# MSPM0G350X register map
Vendor: Texas Instruments; File version: This preliminary header file does not have a version number - build date: 2023-02-21 16:25:48
CPU: CM0 r0p1, little endian, MPU, no FPU, 3 interrupt priority bits
Registers are 32-bit, read-write, reset 0x0 unless marked. A register's access mark holds for its fields unless they carry their own. Offsets are from the block's base; [hi:lo] are bit positions; {n}, {i} and the like mark numbered series.

## AES — PERIPHERALREGION
Base 0x40442000
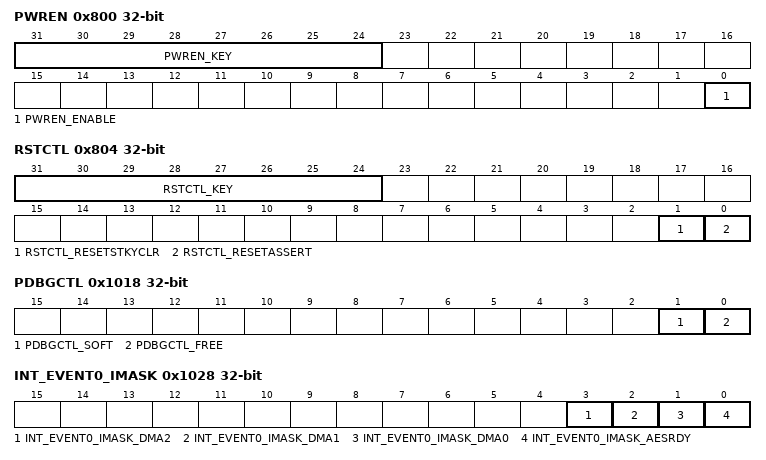
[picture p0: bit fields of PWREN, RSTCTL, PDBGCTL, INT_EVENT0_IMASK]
0x800 PWREN — Power enable
  [31:24] PWREN_KEY wo — KEY to allow Power State Change
    38=PWREN_KEY_UNLOCK_W (_TO_UNLOCK_W_)
  [0] PWREN_ENABLE — Enable the power
    0=PWREN_ENABLE_DISABLE (DISABLE); 1=PWREN_ENABLE_ENABLE (ENABLE)
0x804 RSTCTL wo — Reset Control
  [31:24] RSTCTL_KEY — Unlock key
    177=RSTCTL_KEY_UNLOCK_W (_TO_UNLOCK_W_)
  [1] RSTCTL_RESETSTKYCLR — Clear the RESETSTKY bit in the STAT register
    0=RSTCTL_RESETSTKYCLR_NOP (NOP); 1=RSTCTL_RESETSTKYCLR_CLR (CLR)
  [0] RSTCTL_RESETASSERT — Assert reset to the peripheral
    0=RSTCTL_RESETASSERT_NOP (NOP); 1=RSTCTL_RESETASSERT_ASSERT (ASSERT)
0x814 STAT ro — Status Register
  [16] STAT_RESETSTKY — This bit indicates, if the peripheral was reset, since this bit was cleared by RESETSTKYCLR in the RSTCTL register
    0=STAT_RESETSTKY_NORES (NORES); 1=STAT_RESETSTKY_RESET (RESET)
0x1018 PDBGCTL — Peripheral Debug Control
  [1] PDBGCTL_SOFT — Soft halt boundary control. This function is only available, if [FREE] is set to 'STOP'
    0=PDBGCTL_SOFT_IMMEDIATE (IMMEDIATE); 1=PDBGCTL_SOFT_DELAYED (DELAYED)
  [0] PDBGCTL_FREE — Free run control
    0=PDBGCTL_FREE_STOP (STOP); 1=PDBGCTL_FREE_RUN (RUN)
0x1020 INT_EVENT0_IIDX ro — Interrupt Index Register
  [7:0] INT_EVENT0_IIDX_STAT — Interrupt index status
    0=INT_EVENT0_IIDX_STAT_NO_INTR (NO_INTR); 1=INT_EVENT0_IIDX_STAT_AESRDY (AESRDY); 2=INT_EVENT0_IIDX_STAT_DMA0 (DMA0); 3=INT_EVENT0_IIDX_STAT_DMA1 (DMA1); 4=INT_EVENT0_IIDX_STAT_DMA2 (DMA2)
0x1028 INT_EVENT0_IMASK — Interrupt mask
  [3] INT_EVENT0_IMASK_DMA2 — DMA2 event mask.
    0=INT_EVENT0_IMASK_DMA2_CLR (CLR); 1=INT_EVENT0_IMASK_DMA2_SET (SET)
  [2] INT_EVENT0_IMASK_DMA1 — DMA1 event mask.
    0=INT_EVENT0_IMASK_DMA1_CLR (CLR); 1=INT_EVENT0_IMASK_DMA1_SET (SET)
  [1] INT_EVENT0_IMASK_DMA0 — DMA0 event mask.
    0=INT_EVENT0_IMASK_DMA0_CLR (CLR); 1=INT_EVENT0_IMASK_DMA0_SET (SET)
  [0] INT_EVENT0_IMASK_AESRDY — AES ready interrupt, set when the selected AES operation was completed and the result can be read from AESADOUT.
    0=INT_EVENT0_IMASK_AESRDY_CLR (CLR); 1=INT_EVENT0_IMASK_AESRDY_SET (SET)
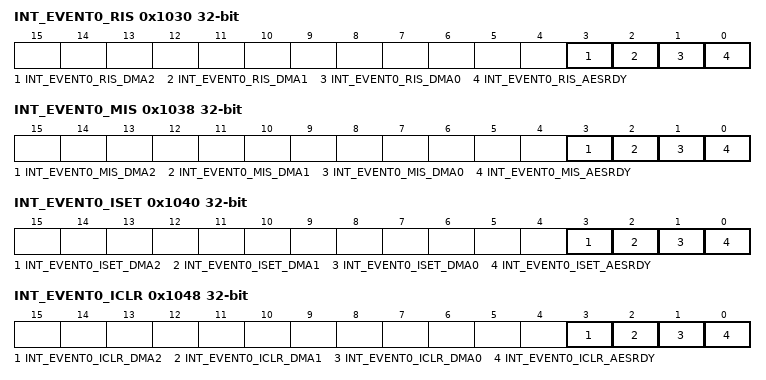
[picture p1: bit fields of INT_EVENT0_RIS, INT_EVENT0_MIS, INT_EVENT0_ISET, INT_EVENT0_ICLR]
0x1030 INT_EVENT0_RIS ro — Raw interrupt status
  [3] INT_EVENT0_RIS_DMA2 — DMA2 event
    0=INT_EVENT0_RIS_DMA2_CLR (CLR); 1=INT_EVENT0_RIS_DMA2_SET (SET)
  [2] INT_EVENT0_RIS_DMA1 — DMA1 event
    0=INT_EVENT0_RIS_DMA1_CLR (CLR); 1=INT_EVENT0_RIS_DMA1_SET (SET)
  [1] INT_EVENT0_RIS_DMA0 — DMA0 event
    0=INT_EVENT0_RIS_DMA0_CLR (CLR); 1=INT_EVENT0_RIS_DMA0_SET (SET)
  [0] INT_EVENT0_RIS_AESRDY — AES ready interrupt, set when the selected AES operation was completed and the result can be read from AESADOUT.
    0=INT_EVENT0_RIS_AESRDY_CLR (CLR); 1=INT_EVENT0_RIS_AESRDY_SET (SET)
0x1038 INT_EVENT0_MIS ro — Masked interrupt status
  [3] INT_EVENT0_MIS_DMA2 — DMA2 event
    0=INT_EVENT0_MIS_DMA2_CLR (CLR); 1=INT_EVENT0_MIS_DMA2_SET (SET)
  [2] INT_EVENT0_MIS_DMA1 — DMA1 event
    0=INT_EVENT0_MIS_DMA1_CLR (CLR); 1=INT_EVENT0_MIS_DMA1_SET (SET)
  [1] INT_EVENT0_MIS_DMA0 — DMA0 event
    0=INT_EVENT0_MIS_DMA0_CLR (CLR); 1=INT_EVENT0_MIS_DMA0_SET (SET)
  [0] INT_EVENT0_MIS_AESRDY — AES ready interrupt, set when the selected AES operation was completed and the result can be read from AESADOUT.
    0=INT_EVENT0_MIS_AESRDY_CLR (CLR); 1=INT_EVENT0_MIS_AESRDY_SET (SET)
0x1040 INT_EVENT0_ISET wo — Interrupt set
  [3] INT_EVENT0_ISET_DMA2 — DMA2
    0=INT_EVENT0_ISET_DMA2_NO_EFFECT (NO_EFFECT); 1=INT_EVENT0_ISET_DMA2_SET (SET)
  [2] INT_EVENT0_ISET_DMA1 — DMA1
    0=INT_EVENT0_ISET_DMA1_NO_EFFECT (NO_EFFECT); 1=INT_EVENT0_ISET_DMA1_SET (SET)
  [1] INT_EVENT0_ISET_DMA0 — DMA0
    0=INT_EVENT0_ISET_DMA0_NO_EFFECT (NO_EFFECT); 1=INT_EVENT0_ISET_DMA0_SET (SET)
  [0] INT_EVENT0_ISET_AESRDY — AES ready interrupt, set when the selected AES operation was completed and the result can be read from AESADOUT.
    0=INT_EVENT0_ISET_AESRDY_NO_EFFECT (NO_EFFECT); 1=INT_EVENT0_ISET_AESRDY_SET (SET)
0x1048 INT_EVENT0_ICLR wo — Interrupt clear
  [3] INT_EVENT0_ICLR_DMA2 — DMA2
    0=INT_EVENT0_ICLR_DMA2_NO_EFFECT (NO_EFFECT); 1=INT_EVENT0_ICLR_DMA2_CLR (CLR)
  [2] INT_EVENT0_ICLR_DMA1 — DMA1
    0=INT_EVENT0_ICLR_DMA1_NO_EFFECT (NO_EFFECT); 1=INT_EVENT0_ICLR_DMA1_CLR (CLR)
  [1] INT_EVENT0_ICLR_DMA0 — DMA0
    0=INT_EVENT0_ICLR_DMA0_NO_EFFECT (NO_EFFECT); 1=INT_EVENT0_ICLR_DMA0_CLR (CLR)
  [0] INT_EVENT0_ICLR_AESRDY — AES ready interrupt, set when the selected AES operation was completed and the result can be read from AESADOUT.
    0=INT_EVENT0_ICLR_AESRDY_NO_EFFECT (NO_EFFECT); 1=INT_EVENT0_ICLR_AESRDY_CLR (CLR)
{0x1020+0x30*i} INT_EVENT{i}_IIDX ro (i=1..3) — Interrupt Index Register
  [7:0] INT_EVENT{i}_IIDX_STAT — Interrupt index status
    0=INT_EVENT{i}_IIDX_STAT_NO_INTR (NO_INTR); {i+1}=INT_EVENT{i}_IIDX_STAT_DMA{i-1} (DMA{i-1})
{0x1028+0x30*i} INT_EVENT{i}_IMASK (i=1..3) — Interrupt mask
  [{i}] INT_EVENT{i}_IMASK_DMA{i-1} — DMA{i-1} event mask.
    0=INT_EVENT{i}_IMASK_DMA{i-1}_CLR (CLR); 1=INT_EVENT{i}_IMASK_DMA{i-1}_SET (SET)
{0x1030+0x30*i} INT_EVENT{i}_RIS ro (i=1..3) — Raw interrupt status
  [{i}] INT_EVENT{i}_RIS_DMA{i-1} — DMA{i-1} event
    0=INT_EVENT{i}_RIS_DMA{i-1}_CLR (CLR); 1=INT_EVENT{i}_RIS_DMA{i-1}_SET (SET)
{0x1038+0x30*i} INT_EVENT{i}_MIS ro (i=1..3) — Masked interrupt status
  [{i}] INT_EVENT{i}_MIS_DMA{i-1} — DMA{i-1} event
    0=INT_EVENT{i}_MIS_DMA{i-1}_CLR (CLR); 1=INT_EVENT{i}_MIS_DMA{i-1}_SET (SET)
0x1070 INT_EVENT1_ISET wo — Interrupt set
  [1] INT_EVENT1_ISET_DMA0 — DMA0
    0=INT_EVENT1_ISET_DMA0_NO_EFFECT (NO_EFFECT); 1=INT_EVENT1_ISET_DMA0_SET (SET)
{0x1048+0x30*i} INT_EVENT{i}_ICLR wo (i=1..3) — Interrupt clear
  [{i}] INT_EVENT{i}_ICLR_DMA{i-1} — DMA{i-1} event
    0=INT_EVENT{i}_ICLR_DMA{i-1}_NO_EFFECT (NO_EFFECT); 1=INT_EVENT{i}_ICLR_DMA{i-1}_CLR (CLR)
0x10A0 INT_EVENT2_ISET wo — Interrupt set
  [2] INT_EVENT2_ISET_DMA1 — DMA1 event
    0=INT_EVENT2_ISET_DMA1_NO_EFFECT (NO_EFFECT); 1=INT_EVENT2_ISET_DMA1_SET (SET)
0x10D0 INT_EVENT3_ISET wo — Interrupt set
  [3] INT_EVENT3_ISET_DMA2 — DMA2 event
    0=INT_EVENT3_ISET_DMA2_NO_EFFECT (NO_EFFECT); 1=INT_EVENT3_ISET_DMA2_SET (SET)
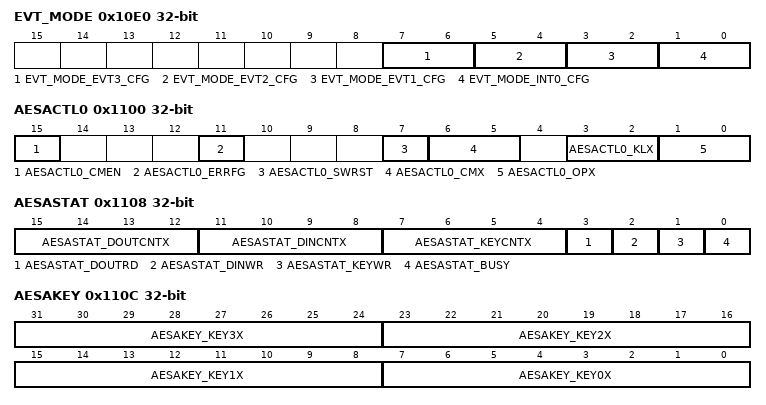
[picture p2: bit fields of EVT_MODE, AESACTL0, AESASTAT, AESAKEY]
0x10E0 EVT_MODE — Event Mode
  [7:6] EVT_MODE_EVT3_CFG ro — Event line mode select for event corresponding to [IPSTANDARD.INT_EVENT2]
    0=EVT_MODE_EVT3_CFG_DISABLE (DISABLE); 1=EVT_MODE_EVT3_CFG_SOFTWARE (SOFTWARE); 2=EVT_MODE_EVT3_CFG_HARDWARE (HARDWARE)
  [5:4] EVT_MODE_EVT2_CFG ro — Event line mode select for event corresponding to [IPSTANDARD.INT_EVENT2]
    0=EVT_MODE_EVT2_CFG_DISABLE (DISABLE); 1=EVT_MODE_EVT2_CFG_SOFTWARE (SOFTWARE); 2=EVT_MODE_EVT2_CFG_HARDWARE (HARDWARE)
  [3:2] EVT_MODE_EVT1_CFG ro — Event line mode select for event corresponding to [IPSTANDARD.INT_EVENT1]
    0=EVT_MODE_EVT1_CFG_DISABLE (DISABLE); 1=EVT_MODE_EVT1_CFG_SOFTWARE (SOFTWARE); 2=EVT_MODE_EVT1_CFG_HARDWARE (HARDWARE)
  [1:0] EVT_MODE_INT0_CFG ro — Event line mode select for event corresponding to [IPSTANDARD.INT_EVENT0]
    0=EVT_MODE_INT0_CFG_DISABLE (DISABLE); 1=EVT_MODE_INT0_CFG_SOFTWARE (SOFTWARE); 2=EVT_MODE_INT0_CFG_HARDWARE (HARDWARE)
0x1100 AESACTL0 — AES accelerator control register 0
  [15] AESACTL0_CMEN — AESCMEN enables the support of the cipher modes ECB, CBC, OFB and CFB together with the DMA. Writes are ignored when AESCMEN = 1 and AESBLKCNTx > 0. 0 = No DMA triggers are generated. 1 = DMA cipher mode support operation is enabled and the corresponding DMA triggers are generated.
    0=AESACTL0_CMEN_DISABLE (DISABLE); 1=AESACTL0_CMEN_ENABLE (ENABLE)
  [11] AESACTL0_ERRFG — AES error flag. AESAKEY or AESADIN were written while an AES operation was in progress. The bit must be cleared by software. 0b = No error 1b = Error occurred
    0=AESACTL0_ERRFG_NOERR (NOERR); 1=AESACTL0_ERRFG_ERR (ERR)
  [7] AESACTL0_SWRST — AES software reset. Immediately resets the complete AES accelerator module even when busy except for the AESRDYIE, the AESKLx and the AESOPx bits. It also clears the (internal) state memory. The AESSWRST bit is automatically reset and is always read as zero. 0b = No reset 1b = Reset AES accelerator module
    0=AESACTL0_SWRST_NORST (NORST); 1=AESACTL0_SWRST_RST (RST)
  [6:5] AESACTL0_CMX — AES cipher mode select. These bits are ignored for AESCMEN = 0. Writes are ignored when AESCMEN = 1 and AESBLKCNTx > 0. 00b = ECB 01b = CBC 10b = OFB 11b = CFB
    0=AESACTL0_CMX_ECB (ECB); 1=AESACTL0_CMX_CBC (CBC); 2=AESACTL0_CMX_OFB (OFB); 3=AESACTL0_CMX_CFB (CFB)
  [3:2] AESACTL0_KLX — AES key length. These bits define which of the 1 AES standards is performed. The AESKLx bits are not reset by AESSWRST = 1. Writes are ignored when AESCMEN = 1 and AESBLKCNTx > 0.
    0=AESACTL0_KLX_AES128 (AES128); 2=AESACTL0_KLX_AES256 (AES256)
  [1:0] AESACTL0_OPX — AES operation. The AESOPx bits are not reset by AESSWRST = 1. Writes are ignored when AESCMEN = 1 and AESBLKCNTx > 0. 00b = Encryption. 01b = Decryption. The provided key is the same key used for encryption. 10b = Generate first round key required for decryption. 11b = Decryption. The provided key is the first round key required for decryption.
    {v}=AESACTL0_OPX_OP{v} (OP{v}) (v=0..3)
0x1104 AESACTL1 — AES accelerator control register 1
  [7:0] AESACTL1_BLKCNTX — Cipher Block Counter. Number of blocks to be encrypted or decrypted with block cipher modes enabled (AESCMEN = 1). Ignored if AESCMEN = 0. The block counter decrements with each performed encryption or decryption. Writes are ignored when AESCMEN = 1 and AESBLKCNTx > 0.
    0=AESACTL1_BLKCNTX_MINNUM (MINNUM); 255=AESACTL1_BLKCNTX_ENABLE (ENABLE)
0x1108 AESASTAT — aes accelerator status register
  [15:12] AESASTAT_DOUTCNTX ro — Bytes read from AESADOUT. Reset when AESDOUTRD is reset. If AESDOUTCNTx = 0 and AESDOUTRD = 0, no bytes were read. If AESDOUTCNTx = 0 and AESDOUTRD = 1, all bytes were read.
    0=AESASTAT_DOUTCNTX_MINNUM (MINNUM); 15=AESASTAT_DOUTCNTX_MAXNUM (MAXNUM)
  [11:8] AESASTAT_DINCNTX ro — Bytes written to AESADIN, AESAXDIN or AESAXIN. Reset when AESDINWR is reset. If AESDINCNTx = 0 and AESDINWR = 0, no bytes were written. If AESDINCNTx = 0 and AESDINWR = 1, all bytes were written.
    0=AESASTAT_DINCNTX_MINNUM (MINNUM); 15=AESASTAT_DINCNTX_MAXNUM (MAXNUM)
  [7:4] AESASTAT_KEYCNTX ro — Bytes written to AESAKEY when AESKLx = 00, half-words written to AESAKEY if AESKLx = b10. Reset when AESKEYWR is reset. If AESKEYCNTx = 0 and AESKEYWR = 0, no bytes were written. If AESKEYCNTx = 0 and AESKEYWR = 1, all bytes were written.
    0=AESASTAT_KEYCNTX_MINNUM (MINNUM); 15=AESASTAT_KEYCNTX_MAXNUM (MAXNUM)
  [3] AESASTAT_DOUTRD ro — All 16 bytes read from AESADOUT. AESDOUTRD is reset by PUC, AESSWRST, an error condition, changing AESOPx, changing AESKLx, when the AES accelerator is busy, and when the output data is read again. 0 = Not all bytes read 1 = All bytes read
    0=AESASTAT_DOUTRD_NALL (NALL); 1=AESASTAT_DOUTRD_ALL (ALL)
  [2] AESASTAT_DINWR — All 16 bytes written to AESADIN, AESAXDIN or AESAXIN. Changing its state by software also resets the AESDINCNTx bits. AESDINWR is reset by PUC, AESSWRST, an error condition, changing AESOPx, changing AESKLx, the start to (over)write the data, and when the AES accelerator is busy. Because it is reset when AESOPx or AESKLx is changed it can be set by software again to indicate that the current data is still valid. 0 = Not all bytes written 1 = All bytes written
    0=AESASTAT_DINWR_NALL (NALL); 1=AESASTAT_DINWR_ALL (ALL)
  [1] AESASTAT_KEYWR — All bytes written to AESAKEY. This bit can be modified by software but it must not be reset by software (10) if AESCMEN=1. Changing its state by software also resets the AESKEYCNTx bits. AESKEYWR is reset by PUC, AESSWRST, an error condition, changing AESOPx, changing AESKLx, and the start to (over)write a new key. Because it is reset when AESOPx is changed it can be set by software again to indicate that the loaded key is still valid.
    0=AESASTAT_KEYWR_NALL (NALL); 1=AESASTAT_KEYWR_ALL (ALL)
  [0] AESASTAT_BUSY ro — AES accelerator module busy; encryption, decryption, or key generation in progress. 0 = Not busy 1 = Busy
    0=AESASTAT_BUSY_IDLE (IDLE); 1=AESASTAT_BUSY_BUSY (BUSY)
0x110C AESAKEY wo — aes accelerator key register
  [31:24] AESAKEY_KEY3X — AES key byte n+3 when AESAKEY is written as word. Do not use these bits for byte access. Do not mix word and byte access. Always reads as zero. The key is reset by PUC or by AESSWRST = 1.
    0=AESAKEY_KEY3X_MINNUM (MINNUM); 255=AESAKEY_KEY3X_MAXNUM (MAXNUM)
  [23:16] AESAKEY_KEY2X — AES key byte n+2 when AESAKEY is written as word. Do not use these bits for byte access. Do not mix word and byte access. Always reads as zero. The key is reset by PUC or by AESSWRST = 1.
    0=AESAKEY_KEY2X_MINNUM (MINNUM); 255=AESAKEY_KEY2X_MAXNUM (MAXNUM)
  [15:8] AESAKEY_KEY1X — AES key byte n+1 when AESAKEY is written as word. Do not use these bits for byte access. Do not mix word and byte access. Always reads as zero. The key is reset by PUC or by AESSWRST = 1.
    0=AESAKEY_KEY1X_MINNUM (MINNUM); 255=AESAKEY_KEY1X_MAXNUM (MAXNUM)
  [7:0] AESAKEY_KEY0X — AES key byte n when AESAKEY is written as word. AES next key byte when AESAKEY is written as byte. Do not mix word and byte access. Always reads as zero. The key is reset by PUC or by AESSWRST = 1.
    0=AESAKEY_KEY0X_MINNUM (MINNUM); 255=AESAKEY_KEY0X_MAXNUM (MAXNUM)
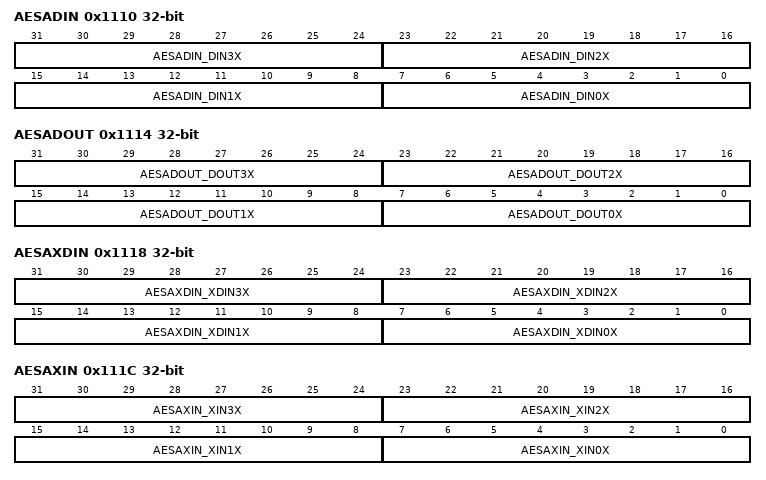
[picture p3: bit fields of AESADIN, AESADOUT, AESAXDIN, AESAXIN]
0x1110 AESADIN wo — aes accelerator data in register
  [31:24] AESADIN_DIN3X — AES data in byte n+3 when AESADIN is written as word. Do not use these bits for byte access. Do not mix word and byte access. Always reads as zero.
    0=AESADIN_DIN3X_MINNUM (MINNUM); 255=AESADIN_DIN3X_MAXNUM (MAXNUM)
  [23:16] AESADIN_DIN2X — AES data in byte n+2 when AESADIN is written as word. Do not use these bits for byte access. Do not mix word and byte access. Always reads as zero.
    0=AESADIN_DIN2X_MINNUM (MINNUM); 255=AESADIN_DIN2X_MAXNUM (MAXNUM)
  [15:8] AESADIN_DIN1X — AES data in byte n+1 when AESADIN is written as word. Do not use these bits for byte access. Do not mix word and byte access. Always reads as zero.
    0=AESADIN_DIN1X_MINNUM (MINNUM); 255=AESADIN_DIN1X_MAXNUM (MAXNUM)
  [7:0] AESADIN_DIN0X — AES data in byte n when AESADIN is written as word. AES next data in byte when AESADIN is written as byte. Do not mix word and byte access. Always reads as zero.
    0=AESADIN_DIN0X_MINNUM (MINNUM); 255=AESADIN_DIN0X_MAXNUM (MAXNUM)
0x1114 AESADOUT ro — aes accelerator data out register
  [31:24] AESADOUT_DOUT3X — AES data out byte n+3 when AESADOUT is read as word. Do not use these bits for byte access. Do not mix word and byte access.
    0=AESADOUT_DOUT3X_MINNUM (MINNUM); 255=AESADOUT_DOUT3X_MAXNUM (MAXNUM)
  [23:16] AESADOUT_DOUT2X — AES data out byte n+2 when AESADOUT is read as word. Do not use these bits for byte access. Do not mix word and byte access.
    0=AESADOUT_DOUT2X_MINNUM (MINNUM); 255=AESADOUT_DOUT2X_MAXNUM (MAXNUM)
  [15:8] AESADOUT_DOUT1X — AES data out byte n+1 when AESADOUT is read as word. Do not use these bits for byte access. Do not mix word and byte access.
    0=AESADOUT_DOUT1X_MINNUM (MINNUM); 255=AESADOUT_DOUT1X_MAXNUM (MAXNUM)
  [7:0] AESADOUT_DOUT0X — AES data out byte n when AESADOUT is read as word. AES next data out byte when AESADOUT is read as byte. Do not mix word and byte access.
    0=AESADOUT_DOUT0X_MINNUM (MINNUM); 255=AESADOUT_DOUT0X_MAXNUM (MAXNUM)
0x1118 AESAXDIN wo — aes accelerator xored data in register
  [31:24] AESAXDIN_XDIN3X — AES data in byte n+3 when AESAXDIN is written as word. Do not use these bits for byte access. Do not mix word and byte access. Always reads as zero.
    0=AESAXDIN_XDIN3X_MINNUM (MINNUM); 255=AESAXDIN_XDIN3X_MAXNUM (MAXNUM)
  [23:16] AESAXDIN_XDIN2X — AES data in byte n+2 when AESAXDIN is written as word. Do not use these bits for byte access. Do not mix word and byte access. Always reads as zero.
    0=AESAXDIN_XDIN2X_MINNUM (MINNUM); 255=AESAXDIN_XDIN2X_MAXNUM (MAXNUM)
  [15:8] AESAXDIN_XDIN1X — AES data in byte n+1 when AESAXDIN is written as word. Do not use these bits for byte access. Do not mix word and byte access. Always reads as zero.
    0=AESAXDIN_XDIN1X_MINNUM (MINNUM); 255=AESAXDIN_XDIN1X_MAXNUM (MAXNUM)
  [7:0] AESAXDIN_XDIN0X — AES data in byte n when AESAXDIN is written as word. AES next data in byte when AESAXDIN is written as byte. Do not mix word and byte access. Always reads as zero.
    0=AESAXDIN_XDIN0X_MINNUM (MINNUM); 255=AESAXDIN_XDIN0X_MAXNUM (MAXNUM)
0x111C AESAXIN wo — aes accelerator xored data in register (no trigger)
  [31:24] AESAXIN_XIN3X — AES data in byte n+3 when AESAXIN is written as word. Do not use these bits for byte access. Do not mix word and byte access. Always reads as zero.
    0=AESAXIN_XIN3X_MINNUM (MINNUM); 255=AESAXIN_XIN3X_MAXNUM (MAXNUM)
  [23:16] AESAXIN_XIN2X — AES data in byte n+2 when AESAXIN is written as word. Do not use these bits for byte access. Do not mix word and byte access. Always reads as zero.
    0=AESAXIN_XIN2X_MINNUM (MINNUM); 255=AESAXIN_XIN2X_MAXNUM (MAXNUM)
  [15:8] AESAXIN_XIN1X — AES data in byte n+1 when AESAXIN is written as word. Do not use these bits for byte access. Do not mix word and byte access. Always reads as zero.
    0=AESAXIN_XIN1X_MINNUM (MINNUM); 255=AESAXIN_XIN1X_MAXNUM (MAXNUM)
  [7:0] AESAXIN_XIN0X — AES data in byte n when AESAXIN is written as word. AES next data in byte when AESAXIN is written as byte. Do not mix word and byte access. Always reads as zero.
    0=AESAXIN_XIN0X_MINNUM (MINNUM); 255=AESAXIN_XIN0X_MAXNUM (MAXNUM)
